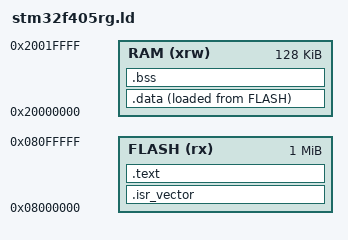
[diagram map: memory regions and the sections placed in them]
/* STM32F405RGT6: 1 MiB internal flash, 128 KiB general SRAM.
 * The separate 64 KiB CCM SRAM is deliberately unused by this first image. */
ENTRY(Reset_Handler)

MEMORY
{
    FLASH (rx)  : ORIGIN = 0x08000000, LENGTH = 1024K
    RAM   (xrw) : ORIGIN = 0x20000000, LENGTH = 128K
}

_estack = ORIGIN(RAM) + LENGTH(RAM);

SECTIONS
{
    .isr_vector :
    {
        . = ALIGN(4);
        KEEP(*(.isr_vector))
        . = ALIGN(4);
    } > FLASH

    .text :
    {
        . = ALIGN(4);
        *(.text.Reset_Handler)
        *(.text*)
        *(.rodata*)
        . = ALIGN(4);
        _etext = .;
    } > FLASH

    .data :
    {
        . = ALIGN(4);
        _sdata = .;
        *(.data*)
        . = ALIGN(4);
        _edata = .;
    } > RAM AT > FLASH
    _sidata = LOADADDR(.data);

    .bss (NOLOAD) :
    {
        . = ALIGN(4);
        _sbss = .;
        *(.bss*)
        *(COMMON)
        . = ALIGN(4);
        _ebss = .;
    } > RAM
}
